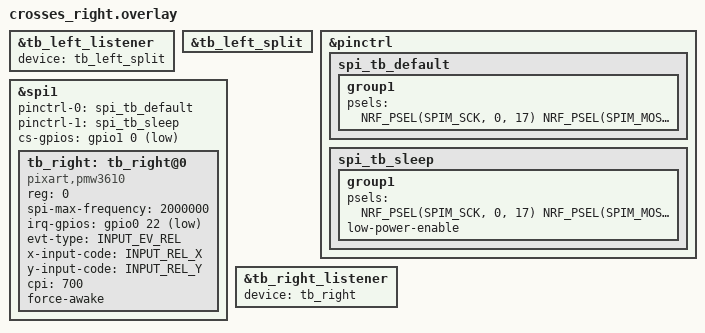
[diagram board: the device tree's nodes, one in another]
#include "crosses_trackball_shared.dtsi"
#include <zephyr/dt-bindings/input/input-event-codes.h>

/* Enable listener for left (peripheral) trackball */
&tb_left_listener {
  status = "okay";
  device = <&tb_left_split>;
};

/* Make the tb_left_split visible on the central core (no device binding here) */
&tb_left_split {
  status = "okay";
};


&pinctrl {
  spi_tb_default: spi_tb_default {
    group1 {
      psels = <
        NRF_PSEL(SPIM_SCK, 0, 17)
        NRF_PSEL(SPIM_MOSI, 0, 20)
        NRF_PSEL(SPIM_MISO, 0, 6)
      >;
    };
  };

  spi_tb_sleep: spi_tb_sleep {
    group1 {
      psels = <
        NRF_PSEL(SPIM_SCK, 0, 17)
        NRF_PSEL(SPIM_MOSI, 0, 20)
        NRF_PSEL(SPIM_MISO, 0, 6)
      >;
      low-power-enable;
    };
  };
};

&spi1 {
  status = "okay";
  pinctrl-0 = <&spi_tb_default>;
  pinctrl-1 = <&spi_tb_sleep>;
  pinctrl-names = "default", "sleep";

  cs-gpios = <&gpio1 0 GPIO_ACTIVE_LOW>; /* P1.00 */

  tb_right: tb_right@0 {
    compatible = "pixart,pmw3610";
    reg = <0>;
    spi-max-frequency = <2000000>;

    irq-gpios = <&gpio0 22 (GPIO_ACTIVE_LOW | GPIO_PULL_UP)>;

    evt-type = <INPUT_EV_REL>;
    x-input-code = <INPUT_REL_X>;
    y-input-code = <INPUT_REL_Y>;

    cpi = <700>;
    force-awake;

    /* Adjust behavior as needed */
    /* xy-swap; */
    /* x-invert; */
    /* y-invert; */
  };
};

/* Enable central trackball */
&tb_right_listener {
  status = "okay";
  device = <&tb_right>;
};
